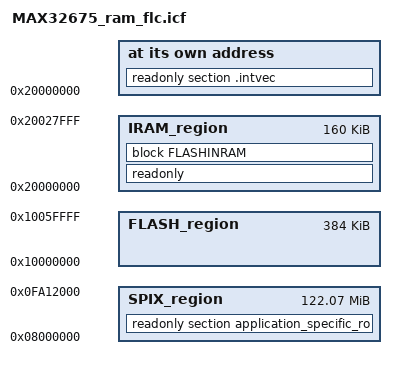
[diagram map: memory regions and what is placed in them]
/*###ICF### Section handled by ICF editor, don't touch! ****/
/*-Editor annotation file-*/
/* IcfEditorFile="$TOOLKIT_DIR$\config\ide\IcfEditor\cortex_v1_1.xml" */
/*-Specials-*/
define symbol __ICFEDIT_intvec_start__ = 0x20000000;
/*-Memory Regions-*/
define symbol __ICFEDIT_region_ROM_start     = 0x00000000;
define symbol __ICFEDIT_region_ROM_end       = 0x00020000;
define symbol __ICFEDIT_region_FLASH_start__ = 0x10000000;
define symbol __ICFEDIT_region_FLASH_end__   = 0x1005FFFF;
define symbol __ICFEDIT_region_SPIX_start__  = 0x08000000;
define symbol __ICFEDIT_region_SPIX_end__    = 0x0FA12000;
define symbol __ICFEDIT_region_IRAM1_start__ = 0x20000000;
define symbol __ICFEDIT_region_IRAM1_end__   = 0x20027FFF;

/*-Sizes-*/
define symbol __ICFEDIT_size_cstack__ = 0x6000;
define symbol __ICFEDIT_size_heap__   = 0x2000;
/**** End of ICF editor section. ###ICF###*/

define memory mem with size = 4G;
define region FLASH_region  =   mem:[from __ICFEDIT_region_FLASH_start__ to __ICFEDIT_region_FLASH_end__];
define region SPIX_region   =   mem:[from __ICFEDIT_region_SPIX_start__ to __ICFEDIT_region_SPIX_end__];
define region IRAM_region   =   mem:[from __ICFEDIT_region_IRAM1_start__ to __ICFEDIT_region_IRAM1_end__];

define block CSTACK    with alignment = 8, size = __ICFEDIT_size_cstack__   { };
define block HEAP      with alignment = 8, size = __ICFEDIT_size_heap__     { };

define block TESTDATA { section ".testdata_space" };

define block FLASHINRAM { section ".flashprog" };

do not initialize  { section .noinit };
initialize by copy { readwrite };

if (isdefinedsymbol(__USE_DLIB_PERTHREAD))
{
  // Required in a multi-threaded application
  initialize by copy with packing = none { section __DLIB_PERTHREAD };
}

place at address mem:__ICFEDIT_intvec_start__ { readonly section .intvec };

place in SPIX_region  { readonly section application_specific_ro };
/* place in IRAM_region { readonly, readwrite, block TESTDATA, block CSTACK, block HEAP }; */
/* place in IRAM_region { block RamTop with fixed order {readonly, readwrite, block TESTDATA}}; */
place in IRAM_region { readonly, block FLASHINRAM };
place at end of IRAM_region { block RamBottom with fixed order {readwrite, block TESTDATA, block CSTACK, block HEAP} }; 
